# TC80_VXX register map
Vendor: Geneal MCU Ltd.; Series: ARMCM0; File version: 1.2
CPU: CM0 r0p0, little endian, no MPU, no FPU, 2 interrupt priority bits
Registers are 32-bit, read-write, reset 0x0 unless marked. A register's access mark holds for its fields unless they carry their own. Offsets are from the block's base; [hi:lo] are bit positions; {n}, {i} and the like mark numbered series.

## PLU — Program logic unit
Base 0x49006000
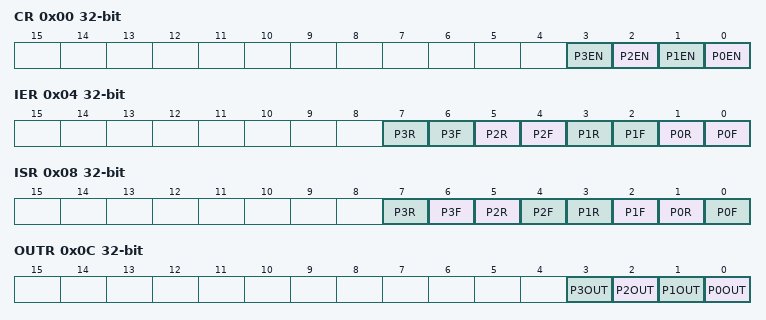
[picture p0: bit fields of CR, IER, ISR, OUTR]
0x00 CR — Control register
  [n] P{n}EN (n=0..3) — PLU {n} enable
    0=Disable (PLU {n} disabled); 1=Enable (PLU {n} enabled)
0x04 IER — Interrupt enable register
  [2n+1] P{n}R (n=0..3) — PLU {n} rise edge interrupt enable
    0=Disable (Rise edge interrupt disabled); 1=Enable (Rise edge interrupt enabled)
  [2n] P{n}F (n=0..3) — PLU {n} fall edge interrupt enable
    0=Disable (Fall edge interrupt disabled); 1=Enable (Fall edge interrupt enabled)
0x08 ISR — Interrupt status register
  [2n+1] P{n}R (n=0..3) — PLU {n} rise edge interrupt flag
    0=No_P{n}R (Rise edge interrupt has no occured); 1=P{n}R_Occured (Rise edge interrupt has occured)
  [6] P3F — PLU 3 fall edge interrupt flag
    0=N0_P3F (Fall edge interrupt has no occured); 1=P3F_Occured (Fall edge interrupt has occured)
  [4] P2F — PLU 2 fall edge interrupt flag
    0=No_P2F (Fall edge interrupt has no occured); 1=P2F_Occured (Fall edge interrupt has occured)
  [2] P1F — PLU 1 fall edge interrupt flag
    0=No_P1F (Fall edge interrupt has no occured); 1=P1F_Occured (Fall edge interrupt has occured)
  [0] P0F — PLU 0 fall edge interrupt flag
    0=No_P0F (Fall edge interrupt has no occured); 1=P0F_Occured (Fall edge interrupt has occured)
0x0C OUTR — Output data register
  [n] P{n}OUT (n=0..3) — PLU {n} output data
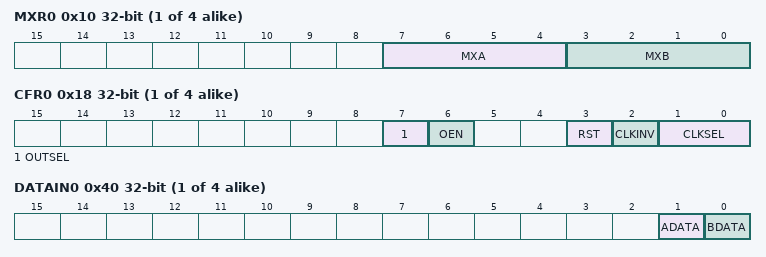
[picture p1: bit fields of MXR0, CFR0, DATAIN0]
{0x10+0xC*i} MXR{i} (i=0..3) — PLU {i} mux input source select register
  [7:4] MXA — Mux a input source select
  [3:0] MXB — Mux b input source select
{0x14+0xC*i} FNR{i} (i=0..3) — PLU {i} function select register
  [7:0] FNSEL — Function select
{0x18+0xC*i} CFR{i} (i=0..3) — PLU {i} control register
  [7] OUTSEL — LUT output select from DFF or not from DFF
  [6] OEN — PLU async output to GPIO PAD enable
  [3] RST — DFF register reset
  [2] CLKINV — DFF register clk select
  [1:0] CLKSEL — D flip-flop clock source select
    0=Carry_In (Carry bit as clock source); 1=MXA_Input (Mux A as clock source); 2=System clock as clock source; 3=Peripheral as clock source
{0x40+4i} DATAIN{i} (i=0..3) — PLU {i} data input register
  [1] ADATA — Mux A input data
  [0] BDATA — Mux B input data

## DAC0 — Digital-to-analog converter
Base 0x49007400
Same registers: DAC1 0x49007800
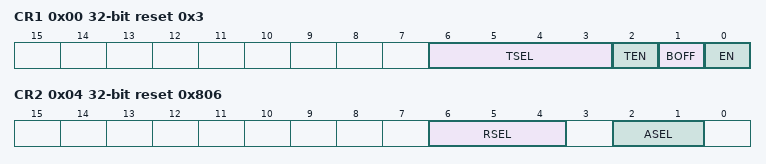
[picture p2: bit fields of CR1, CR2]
0x00 CR1 reset 0x3 — Control register 1
  [6:3] TSEL — DAC channel select
  [2] TEN — DAC channel trigger enable
    0=Diable (DAC channel trigger disabled); 1=Enable (DAC channel trigger enabled)
  [1] BOFF — DAC output buffer off
    0=Off (DAC output buffer enabled); 1=On (DAC output buffer disabled)
  [0] EN — DAC enable
    0=Diable (DAC disabled); 1=Enable (DAC enabled)
0x04 CR2 reset 0x806 — Control register 2
  [6:4] RSEL — Refenrence voltage select
    0=VDD (Select VDD as DAC's refenrence voltage); 1=ADC (Select ADC as DAC's refenrence voltage)
  [2:1] ASEL — Data alignment select
    0=12bits_Right_Align; 1=12bits_Left_Align; 2=8bits_Right_Align
0x08 SOFTRGR — Software trigger register
  [0] TRG — Software trigger
    0=Diable (DAC software trigger disabled); 1=Enable (DAC software trigger enabled)
0x0C DHR — DAC data hold register
  [11:0] DH — Data hold
0x10 DOR — DAC data output register
  [11:0] DO — Data output

## IWDT — Independent watchdog
Base 0x49009000
0x00 KR — Key register
  [15:0] KR — Key value
0x04 PR — Prescaler register
  [2:0] PR — Prescaler divider
    0=Div4 (Divider by 4); 1=Div8 (Divider by 8); 2=Div16 (Divider by 16); 3=Div32 (Divider by 32); 4=Div64 (Divider by 64); 5=Div128 (Divider by 128); 6=Div256 (Divider by 256)
0x08 RLR reset 0xFFF — Reload register
  [11:0] RLR — Watchdog counter reload value
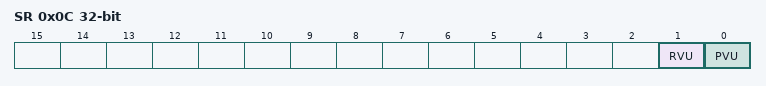
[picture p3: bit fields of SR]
0x0C SR ro — Status register
  [1] RVU — Watchdog counter reload value update status
    0=Done (Update done); 1=On_Going (Update ongoing)
  [0] PVU — Watchdog prescaler value update status
    0=Done (Update done); 1=On_Going (Update ongoing)
0x10 IER — Interrupt enable register
  [0] IE — Watchdog Interrupt Enable
    0=Disable (IWDT interrupt disabled); 1=Enable (IWDT interrupt enabled)
0x14 ISR — Interrupt flag register
  [0] IF — Watchdog Interrupt Flag
    0=Clean_Flag (IWDT interrupt has no occured); 1=Interrupt_Occured (IWDT interrupt has occured)
0x18 CER — IWDT enable register
  [0] CE — Watchdog Enable in SWD mode
    0=Disable (IWDT disabled in SWD mode); 1=Enable (IWDT enabled in SWD mode)
